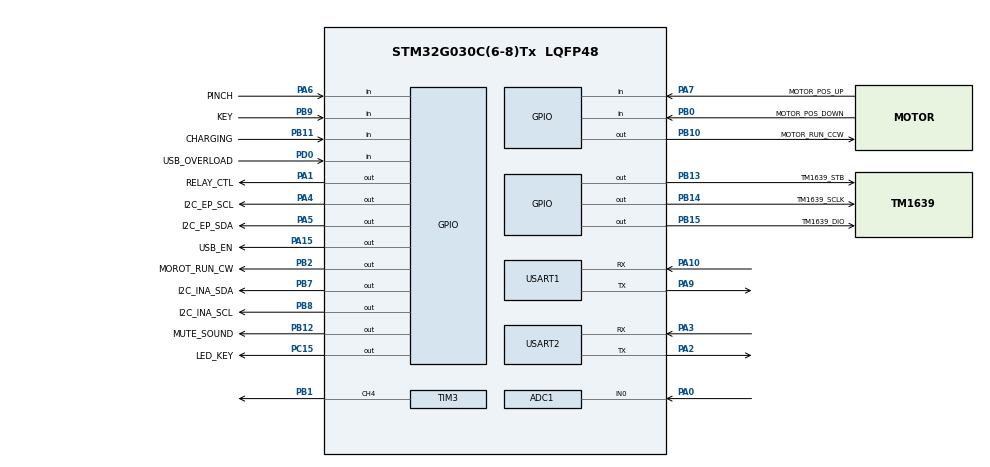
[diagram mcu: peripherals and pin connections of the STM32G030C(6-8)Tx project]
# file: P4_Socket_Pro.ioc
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ADC1.Channel-0\#ChannelRegularConversion=ADC_CHANNEL_0
ADC1.NbrOfConversionFlag=1
ADC1.Rank-0\#ChannelRegularConversion=1
ADC1.SamplingTime-0\#ChannelRegularConversion=ADC_SAMPLINGTIME_COMMON_1
ADC1.SelectedChannel=ADC_CHANNEL_0
ADC1.master=1
Dma.ADC1.0.Direction=DMA_PERIPH_TO_MEMORY
Dma.ADC1.0.EventEnable=DISABLE
Dma.ADC1.0.Instance=DMA1_Channel1
Dma.ADC1.0.MemDataAlignment=DMA_MDATAALIGN_HALFWORD
Dma.ADC1.0.MemInc=DMA_MINC_ENABLE
Dma.ADC1.0.Mode=DMA_NORMAL
Dma.ADC1.0.PeriphDataAlignment=DMA_PDATAALIGN_HALFWORD
Dma.ADC1.0.PeriphInc=DMA_PINC_DISABLE
Dma.ADC1.0.Polarity=HAL_DMAMUX_REQ_GEN_RISING
Dma.ADC1.0.Priority=DMA_PRIORITY_LOW
Dma.ADC1.0.RequestNumber=1
Dma.ADC1.0.SignalID=NONE
Dma.ADC1.0.SyncEnable=DISABLE
Dma.ADC1.0.SyncPolarity=HAL_DMAMUX_SYNC_NO_EVENT
Dma.ADC1.0.SyncRequestNumber=1
Dma.ADC1.0.SyncSignalID=NONE
Dma.Request0=ADC1
Dma.Request1=USART2_RX
Dma.Request2=USART2_TX
Dma.Request3=USART1_RX
Dma.Request4=USART1_TX
Dma.USART1_RX.3.Direction=DMA_PERIPH_TO_MEMORY
Dma.USART1_RX.3.EventEnable=DISABLE
Dma.USART1_RX.3.Instance=DMA1_Channel4
Dma.USART1_RX.3.MemDataAlignment=DMA_MDATAALIGN_BYTE
Dma.USART1_RX.3.MemInc=DMA_MINC_ENABLE
Dma.USART1_RX.3.Mode=DMA_NORMAL
Dma.USART1_RX.3.PeriphDataAlignment=DMA_PDATAALIGN_BYTE
Dma.USART1_RX.3.PeriphInc=DMA_PINC_DISABLE
Dma.USART1_RX.3.Polarity=HAL_DMAMUX_REQ_GEN_RISING
Dma.USART1_RX.3.Priority=DMA_PRIORITY_LOW
Dma.USART1_RX.3.RequestNumber=1
Dma.USART1_RX.3.SignalID=NONE
Dma.USART1_RX.3.SyncEnable=DISABLE
Dma.USART1_RX.3.SyncPolarity=HAL_DMAMUX_SYNC_NO_EVENT
Dma.USART1_RX.3.SyncRequestNumber=1
Dma.USART1_RX.3.SyncSignalID=NONE
Dma.USART1_TX.4.Direction=DMA_MEMORY_TO_PERIPH
Dma.USART1_TX.4.EventEnable=DISABLE
Dma.USART1_TX.4.Instance=DMA1_Channel5
Dma.USART1_TX.4.MemDataAlignment=DMA_MDATAALIGN_BYTE
Dma.USART1_TX.4.MemInc=DMA_MINC_ENABLE
Dma.USART1_TX.4.Mode=DMA_NORMAL
Dma.USART1_TX.4.PeriphDataAlignment=DMA_PDATAALIGN_BYTE
Dma.USART1_TX.4.PeriphInc=DMA_PINC_DISABLE
Dma.USART1_TX.4.Polarity=HAL_DMAMUX_REQ_GEN_RISING
Dma.USART1_TX.4.Priority=DMA_PRIORITY_LOW
Dma.USART1_TX.4.RequestNumber=1
Dma.USART1_TX.4.SignalID=NONE
Dma.USART1_TX.4.SyncEnable=DISABLE
Dma.USART1_TX.4.SyncPolarity=HAL_DMAMUX_SYNC_NO_EVENT
Dma.USART1_TX.4.SyncRequestNumber=1
Dma.USART1_TX.4.SyncSignalID=NONE
Dma.USART2_RX.1.Direction=DMA_PERIPH_TO_MEMORY
Dma.USART2_RX.1.EventEnable=DISABLE
Dma.USART2_RX.1.Instance=DMA1_Channel2
Dma.USART2_RX.1.MemDataAlignment=DMA_MDATAALIGN_BYTE
Dma.USART2_RX.1.MemInc=DMA_MINC_ENABLE
Dma.USART2_RX.1.Mode=DMA_NORMAL
Dma.USART2_RX.1.PeriphDataAlignment=DMA_PDATAALIGN_BYTE
Dma.USART2_RX.1.PeriphInc=DMA_PINC_DISABLE
Dma.USART2_RX.1.Polarity=HAL_DMAMUX_REQ_GEN_RISING
Dma.USART2_RX.1.Priority=DMA_PRIORITY_LOW
Dma.USART2_RX.1.RequestNumber=1
Dma.USART2_RX.1.SignalID=NONE
Dma.USART2_RX.1.SyncEnable=DISABLE
Dma.USART2_RX.1.SyncPolarity=HAL_DMAMUX_SYNC_NO_EVENT
Dma.USART2_RX.1.SyncRequestNumber=1
Dma.USART2_RX.1.SyncSignalID=NONE
Dma.USART2_TX.2.Direction=DMA_MEMORY_TO_PERIPH
Dma.USART2_TX.2.EventEnable=DISABLE
Dma.USART2_TX.2.Instance=DMA1_Channel3
Dma.USART2_TX.2.MemDataAlignment=DMA_MDATAALIGN_BYTE
Dma.USART2_TX.2.MemInc=DMA_MINC_ENABLE
Dma.USART2_TX.2.Mode=DMA_NORMAL
Dma.USART2_TX.2.PeriphDataAlignment=DMA_PDATAALIGN_BYTE
Dma.USART2_TX.2.PeriphInc=DMA_PINC_DISABLE
Dma.USART2_TX.2.Polarity=HAL_DMAMUX_REQ_GEN_RISING
Dma.USART2_TX.2.Priority=DMA_PRIORITY_LOW
Dma.USART2_TX.2.RequestNumber=1
Dma.USART2_TX.2.SignalID=NONE
Dma.USART2_TX.2.SyncEnable=DISABLE
Dma.USART2_TX.2.SyncPolarity=HAL_DMAMUX_SYNC_NO_EVENT
Dma.USART2_TX.2.SyncRequestNumber=1
Dma.USART2_TX.2.SyncSignalID=NONE
FREERTOS.Tasks01=defaultTask,0,128,StartDefaultTask,Default,NULL,Dynamic,NULL,NULL
Mcu.Family=STM32G0
Mcu.Name=STM32G030C(6-8)Tx
Mcu.Package=LQFP48
NVIC.DMA1_Ch4_5_DMAMUX1_OVR_IRQn=true\:3\:0\:false\:false\:true\:true\:false\:true\:true
NVIC.DMA1_Channel1_IRQn=true\:3\:0\:false\:false\:true\:true\:false\:true\:true
NVIC.DMA1_Channel2_3_IRQn=true\:3\:0\:false\:false\:true\:true\:false\:true\:true
NVIC.TIM14_IRQn=true\:3\:0\:false\:false\:true\:false\:false\:true\:true
NVIC.TIM17_IRQn=true\:3\:0\:false\:false\:true\:true\:true\:true\:true
NVIC.TimeBase=TIM14_IRQn
NVIC.TimeBaseIP=TIM14
NVIC.USART1_IRQn=true\:3\:0\:false\:false\:true\:true\:false\:true\:true
NVIC.USART2_IRQn=true\:3\:0\:false\:false\:true\:true\:false\:true\:true
PA0.Mode=IN0
PA0.Signal=ADC1_IN0
PA1.GPIO_Label=RELAY_CTL
PA1.Signal=GPIO_Output
PA10.Mode=Asynchronous
PA10.Signal=USART1_RX
PA13.Mode=Serial_Wire
PA13.Signal=SYS_SWDIO
PA14-BOOT0.Mode=Serial_Wire
PA14-BOOT0.Signal=SYS_SWCLK
PA15.GPIO_Label=USB_EN
PA15.Signal=GPIO_Output
PA2.Mode=Asynchronous
PA2.Signal=USART2_TX
PA3.Mode=Asynchronous
PA3.Signal=USART2_RX
PA4.GPIO_Label=I2C_EP_SCL
PA4.GPIO_ModeDefaultOutputPP=GPIO_MODE_OUTPUT_OD
PA4.GPIO_PuPd=GPIO_NOPULL
PA4.Signal=GPIO_Output
PA5.GPIO_Label=I2C_EP_SDA
PA5.GPIO_ModeDefaultOutputPP=GPIO_MODE_OUTPUT_OD
PA5.GPIO_PuPd=GPIO_NOPULL
PA5.Signal=GPIO_Output
PA6.GPIO_Label=PINCH
PA6.Signal=GPIO_Input
PA7.GPIO_Label=MOTOR_POS_UP
PA7.Signal=GPIO_Input
PA9.Mode=Asynchronous
PA9.Signal=USART1_TX
PB0.GPIO_Label=MOTOR_POS_DOWN
PB0.Signal=GPIO_Input
PB1.Signal=S_TIM3_CH4
PB10.GPIO_Label=MOTOR_RUN_CCW
PB10.GPIO_PuPd=GPIO_PULLDOWN
PB10.Signal=GPIO_Output
PB11.GPIO_Label=CHARGING
PB11.GPIO_PuPd=GPIO_PULLUP
PB11.Signal=GPIO_Input
PB12.GPIO_Label=MUTE_SOUND
PB12.GPIO_PuPd=GPIO_PULLUP
PB12.Signal=GPIO_Output
PB13.GPIO_Label=TM1639_STB
PB13.Signal=GPIO_Output
PB14.GPIO_Label=TM1639_SCLK
PB14.Signal=GPIO_Output
PB15.GPIO_Label=TM1639_DIO
PB15.Signal=GPIO_Output
PB2.GPIO_Label=MOROT_RUN_CW
PB2.GPIO_PuPd=GPIO_PULLDOWN
PB2.Signal=GPIO_Output
PB7.GPIO_Label=I2C_INA_SDA
PB7.GPIO_ModeDefaultOutputPP=GPIO_MODE_OUTPUT_OD
PB7.GPIO_PuPd=GPIO_NOPULL
PB7.Signal=GPIO_Output
PB8.GPIO_Label=I2C_INA_SCL
PB8.GPIO_ModeDefaultOutputPP=GPIO_MODE_OUTPUT_OD
PB8.GPIO_PuPd=GPIO_NOPULL
PB8.Signal=GPIO_Output
PB9.GPIO_Label=KEY
PB9.GPIO_PuPd=GPIO_PULLUP
PB9.Signal=GPIO_Input
PC15-OSC32_OUT\ (PC15).GPIO_Label=LED_KEY
PC15-OSC32_OUT\ (PC15).GPIO_PuPd=GPIO_PULLDOWN
PC15-OSC32_OUT\ (PC15).Signal=GPIO_Output
PD0.GPIO_Label=USB_OVERLOAD
PD0.Signal=GPIO_Input
ProjectManager.HeapSize=0x200
ProjectManager.StackSize=0x400
ProjectManager.TargetToolchain=MDK-ARM V5.32
RCC.ADCFreq_Value=64000000
RCC.AHBFreq_Value=64000000
RCC.CortexFreq_Value=64000000
RCC.EXTERNAL_CLOCK_VALUE=12288000
RCC.HCLKFreq_Value=64000000
RCC.HSE_VALUE=8000000
RCC.HSI_VALUE=16000000
RCC.LSE_VALUE=32768
RCC.SYSCLKFreq_VALUE=64000000
RCC.SYSCLKSource=RCC_SYSCLKSOURCE_PLLCLK
RCC.VCOOutputFreq_Value=128000000
SH.S_TIM3_CH4.0=TIM3_CH4,PWM Generation4 CH4
TIM17.Prescaler=63
TIM3.Channel-PWM\ Generation4\ CH4=TIM_CHANNEL_4
TIM3.Prescaler=63
USART1.VirtualMode-Asynchronous=VM_ASYNC
USART2.VirtualMode-Asynchronous=VM_ASYNC
VP_FREERTOS_VS_CMSIS_V1.Mode=CMSIS_V1
VP_SYS_VS_tim14.Mode=TIM14
VP_TIM17_VS_ClockSourceINT.Mode=Enable_Timer
board=custom

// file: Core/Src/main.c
/* USER CODE BEGIN Header */
/**
  ******************************************************************************
  * @file           : main.c
  * @brief          : Main program body
  ******************************************************************************
  * @attention
  *
  * Copyright (c) 2025 STMicroelectronics.
  * All rights reserved.
  *
  * This software is licensed under terms that can be found in the LICENSE file
  * in the root directory of this software component.
  * If no LICENSE file comes with this software, it is provided AS-IS.
  *
  ******************************************************************************
  */
/* USER CODE END Header */
#include "main.h"
#include "cmsis_os.h"
#include "adc.h"
#include "dma.h"
#include "tim.h"
#include "usart.h"
#include "gpio.h"

/* USER CODE BEGIN Includes */
#include "bsp.h"
/* USER CODE END Includes */

void SystemClock_Config(void);
void MX_FREERTOS_Init(void);

int main(void)
{

  /* MCU Configuration--------------------------------------------------------*/

  /* Reset of all peripherals, Initializes the Flash interface and the Systick. */
   HAL_Init();

  /* Configure the system clock */
  SystemClock_Config();

  /* Initialize all configured peripherals */
  MX_GPIO_Init();
  MX_DMA_Init();
  MX_ADC1_Init();
  MX_TIM17_Init();
  MX_USART2_UART_Init();
  MX_USART1_UART_Init();
  MX_TIM3_Init();
  /* USER CODE BEGIN 2 */
   bsp_init();
   freeRTOS_Handler();
  /* USER CODE END 2 */

  /* Call init function for freertos objects (in cmsis_os2.c) */
 // MX_FREERTOS_Init();

  /* Start scheduler */
  //osKernelStart();

  /* We should never get here as control is now taken by the scheduler */

  /* Infinite loop */
  while (1)
  {

  }
}

void SystemClock_Config(void)
{
  LL_FLASH_SetLatency(LL_FLASH_LATENCY_2);
  while(LL_FLASH_GetLatency() != LL_FLASH_LATENCY_2)
  {
  }

  /* HSI configuration and activation */
  LL_RCC_HSI_Enable();
  while(LL_RCC_HSI_IsReady() != 1)
  {
  }

  /* Main PLL configuration and activation */
  LL_RCC_PLL_ConfigDomain_SYS(LL_RCC_PLLSOURCE_HSI, LL_RCC_PLLM_DIV_1, 8, LL_RCC_PLLR_DIV_2);
  LL_RCC_PLL_Enable();
  LL_RCC_PLL_EnableDomain_SYS();
  while(LL_RCC_PLL_IsReady() != 1)
  {
  }

  /* Set AHB prescaler*/
  LL_RCC_SetAHBPrescaler(LL_RCC_SYSCLK_DIV_1);

  /* Sysclk activation on the main PLL */
  LL_RCC_SetSysClkSource(LL_RCC_SYS_CLKSOURCE_PLL);
  while(LL_RCC_GetSysClkSource() != LL_RCC_SYS_CLKSOURCE_STATUS_PLL)
  {
  }

  /* Set APB1 prescaler*/
  LL_RCC_SetAPB1Prescaler(LL_RCC_APB1_DIV_1);
  /* Update CMSIS variable (which can be updated also through SystemCoreClockUpdate function) */
  LL_SetSystemCoreClock(64000000);

   /* Update the time base */
  if (HAL_InitTick (TICK_INT_PRIORITY) != HAL_OK)
  {
    Error_Handler();
  }
}

void HAL_TIM_PeriodElapsedCallback(TIM_HandleTypeDef *htim)
{
  if (htim->Instance == TIM14)
  {
    HAL_IncTick();
  }
}

void Error_Handler(void)
{
  __disable_irq();
  while (1)
  {
  }
}
